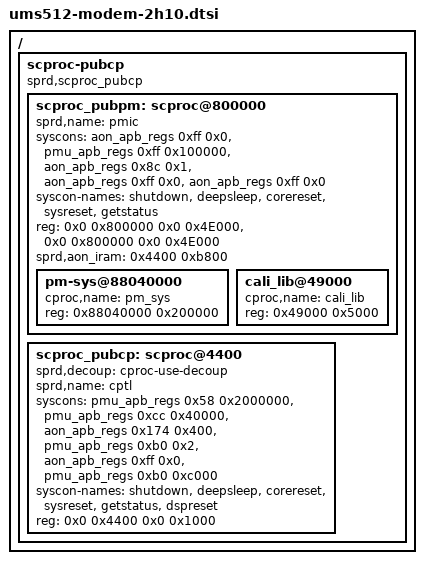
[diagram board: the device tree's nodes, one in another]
/* SPDX-License-Identifier: GPL-2.0-only */
/*
 * ums512-modem-2h10.dtsi - modem subsystem nodes for the Advan Tab VX Lite (T618)
 *
 * Derived 2026-10-04 from:
 *   gpl-source/dts_sprd/arch/arm64/boot/dts/sprd/ums512-modem.dtsi
 *
 * Why this file exists
 * -------------------
 * The stock DTB on this device declares modem@0 (pmsys) and modem@1 with
 * compatible = "unisoc,modem" and the scalar syscon0..syscon5 form, but NO node
 * carries "sprd,scproc" or "sprd,scproc_pubcp". Without such a node the ported
 * sprd_cproc driver cannot probe, and /vendor/bin/modem_control -- which reverse
 * engineering showed drives the modem purely through procfs
 * (/proc/cptl/{start,stop,ldinfo,modemassert} and the pmic directory
 * under /proc/pmic), has nothing to
 * talk to.
 *
 * Provenance, not invention
 * -------------------------
 * Every register in the scproc nodes below is copied verbatim from the reference
 * dtsi, which itself carries the marker comment
 *     "Tab A7 T618 code for SR-AX6189A-01-480"
 * so it is the vendor's own T618 description. It was verified line by line
 * against the stock DTS: the syscon scalar triples on modem@0 and modem@1 in the
 * device DTB are the same register/value pairs the reference uses in its phandle
 * form, e.g.
 *     reference  <&pmu_apb_regs 0x58 0x2000000>   device  <0x02 0x58 0x2000000>
 *     reference  <&aon_apb_regs 0x174 0x400>      device  <0x0c 0x174 0x400>
 *     reference  <&pmu_apb_regs 0xb0 0xc000>      device  <0x02 0xb0 0xc000>
 * where 0x02 is the stock DTB's phandle for pmu_apb_regs and 0x0c for aon_apb_regs.
 * Both nodes also share sprd,decoup = "cproc-use-decoup" and the same six-entry
 * syscon-names ending in "dspreset".
 *
 * The one field that is NOT copied is sprd,name on scproc_pubcp ("cptl"). That is
 * the procfs directory name the driver creates, and /proc/cptl/ is exactly what
 * modem_control opens. It is therefore taken from the observed userland
 * contract, not guessed.
 *
 * This file only DESCRIBES hardware. Enabling CONFIG_SPRD_CPROC and building the
 * kernel are separate steps, and nothing here has been flashed.
 */

/ {
	scproc-pubcp {
		compatible = "sprd,scproc_pubcp";
		#address-cells = <2>;
		#size-cells = <2>;
		ranges;

		scproc_pubpm: scproc@800000 {
			sprd,name = "pmic";
			/* 0xff marks an invalid register offset, per the vendor dtsi. */
			syscons = <&aon_apb_regs 0xff 0x0>,
					<&pmu_apb_regs 0xff 0x100000>,
					<&aon_apb_regs 0x8c 0x1>,
					<&aon_apb_regs 0xff 0x0>,
					<&aon_apb_regs 0xff 0x0>;
			syscon-names = "shutdown", "deepsleep", "corereset",
					"sysreset", "getstatus";
			reg = <0x0 0x800000 0x0 0x4E000>,
			      <0x0 0x800000 0x0 0x4E000>;
			sprd,aon_iram = <0x4400 0xb800>;

			#address-cells = <1>;
			#size-cells = <1>;

			ranges = <0x88040000 0x0 0x88040000 0x200000>,
				 <0x49000 0x0 0x849000 0x5000>;

			pm-sys@88040000 {
				cproc,name = "pm_sys";
				reg = <0x88040000 0x200000>;
			};

			cali_lib@49000 {
				cproc,name = "cali_lib";
				reg = <0x49000 0x5000>;
			};
		};

		scproc_pubcp: scproc@4400 {
			sprd,decoup = "cproc-use-decoup";
			/*
			 * sprd,name is the procfs directory the driver registers.
			 * modem_control opens /proc/cptl/{start,stop,ldinfo,modemassert},
			 * so the name is taken from that observed contract.
			 */
			sprd,name = "cptl";
			syscons = <&pmu_apb_regs 0x58 0x2000000>,
					<&pmu_apb_regs 0xcc 0x40000>,
					<&aon_apb_regs 0x174 0x400>,
					<&pmu_apb_regs 0xb0 0x2>,
					<&aon_apb_regs 0xff 0x0>,
					<&pmu_apb_regs 0xb0 0xc000>;
			syscon-names = "shutdown", "deepsleep", "corereset",
					"sysreset", "getstatus", "dspreset";
			reg = <0x0 0x4400 0x0 0x1000>;
		};
	};
};
